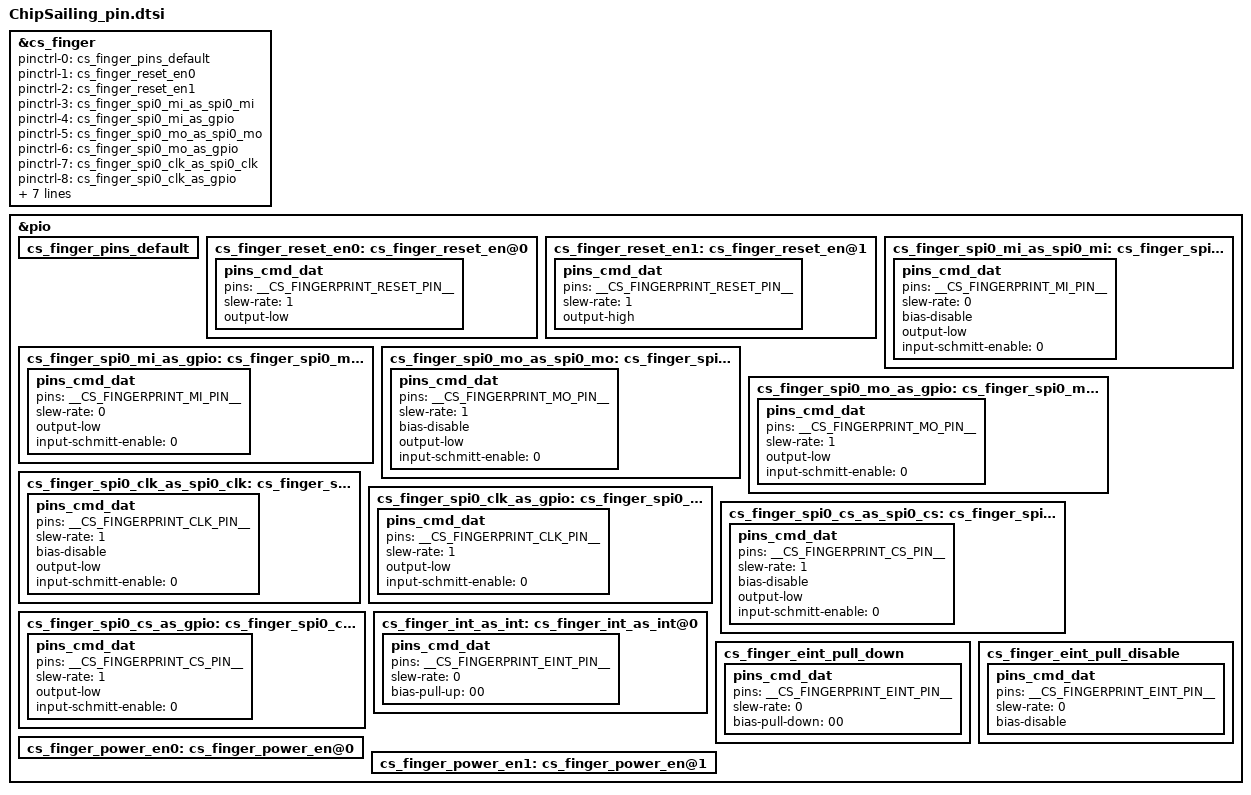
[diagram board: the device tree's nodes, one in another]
/*******************finger pin start ****************/


/*FINGERPRINT GPIO standardization*/
#define __CS_FINGERPRINT_EINT_EN_PIN_NUM__           5
#define __CS_FINGERPRINT_RESET_EN_PIN_NUM__          53
#define __CS_FINGERPRINT_EINT_PIN__                  PINMUX_GPIO5__FUNC_GPIO5
#define __CS_FINGERPRINT_RESET_PIN__                 PINMUX_GPIO53__FUNC_GPIO53 
#define __CS_FINGERPRINT_MI_PIN__          			 PINMUX_GPIO85__FUNC_SPI0_MI
#define __CS_FINGERPRINT_MO_PIN__     				 PINMUX_GPIO87__FUNC_SPI0_MO
#define __CS_FINGERPRINT_CLK_PIN__    				 PINMUX_GPIO88__FUNC_SPI0_CLK
#define __CS_FINGERPRINT_CS_PIN__    				 PINMUX_GPIO86__FUNC_SPI0_CSB

 
 
&cs_finger{
	pinctrl-names = "cs_finger_pins_default", "cs_finger_reset_en0","cs_finger_reset_en1","cs_finger_spi0_mi_as_spi0_mi","cs_finger_spi0_mi_as_gpio",
                          "cs_finger_spi0_mo_as_spi0_mo","cs_finger_spi0_mo_as_gpio","cs_finger_spi0_clk_as_spi0_clk","cs_finger_spi0_clk_as_gpio","cs_finger_spi0_cs_as_spi0_cs",
                          "cs_finger_spi0_cs_as_gpio","cs_finger_int_as_int","cs_finger_eint_pull_down","cs_finger_eint_pull_disable","cs_finger_power_off","cs_finger_power_on";
	pinctrl-0 = <&cs_finger_pins_default>;
	pinctrl-1 = <&cs_finger_reset_en0>;
	pinctrl-2 = <&cs_finger_reset_en1>;
	pinctrl-3 = <&cs_finger_spi0_mi_as_spi0_mi>;
	pinctrl-4 = <&cs_finger_spi0_mi_as_gpio>;
	pinctrl-5 = <&cs_finger_spi0_mo_as_spi0_mo>;
	pinctrl-6 = <&cs_finger_spi0_mo_as_gpio>;
	pinctrl-7 = <&cs_finger_spi0_clk_as_spi0_clk>;
	pinctrl-8= <&cs_finger_spi0_clk_as_gpio>;
	pinctrl-9= <&cs_finger_spi0_cs_as_spi0_cs>;
	pinctrl-10= <&cs_finger_spi0_cs_as_gpio>;
	pinctrl-11= <&cs_finger_int_as_int>;
	pinctrl-12= <&cs_finger_eint_pull_down>;
	pinctrl-13= <&cs_finger_eint_pull_disable>;
	pinctrl-14 = <&cs_finger_power_en0>;
	pinctrl-15 = <&cs_finger_power_en1>;
	status = "okay";
}; 



/*   GPIO standardization */
&pio {
	cs_finger_pins_default:cs_finger_pins_default{
	};
 
	cs_finger_reset_en0:cs_finger_reset_en@0{
		    pins_cmd_dat {
			pins = <__CS_FINGERPRINT_RESET_PIN__>;
			slew-rate = <1>;
			output-low; 
		};
	};
	cs_finger_reset_en1:cs_finger_reset_en@1{
		    pins_cmd_dat {
			pins = <__CS_FINGERPRINT_RESET_PIN__>;
			slew-rate = <1>;
			output-high;
		};
	};
	cs_finger_spi0_mi_as_spi0_mi:cs_finger_spi0_mi_as_spi0_mi@0{
		    pins_cmd_dat {
			pins = <__CS_FINGERPRINT_MI_PIN__>;
			slew-rate = <0>;
			bias-disable;
			output-low;
			input-schmitt-enable = <0>;
		};
	};
 	
	cs_finger_spi0_mi_as_gpio:cs_finger_spi0_mi_as_gpio@0{
		    pins_cmd_dat {
			pins = <__CS_FINGERPRINT_MI_PIN__>;
			slew-rate = <0>;
			output-low;
			input-schmitt-enable = <0>;
		};
	};
	
 
	cs_finger_spi0_mo_as_spi0_mo:cs_finger_spi0_mo_as_spi0_mo@0{
		    pins_cmd_dat {
			pins = <__CS_FINGERPRINT_MO_PIN__>;
			slew-rate = <1>;
			bias-disable;
			output-low;
			input-schmitt-enable = <0>;
		};
	};
 
	cs_finger_spi0_mo_as_gpio:cs_finger_spi0_mo_as_gpio@0{
		    pins_cmd_dat {
			pins = <__CS_FINGERPRINT_MO_PIN__>;
			slew-rate = <1>;
			output-low;
			input-schmitt-enable = <0>;
		};
	};
	cs_finger_spi0_clk_as_spi0_clk:cs_finger_spi0_clk_as_spi0_clk@0{
		    pins_cmd_dat {
			pins = <__CS_FINGERPRINT_CLK_PIN__>;
			slew-rate = <1>;
			bias-disable;
			output-low;
			input-schmitt-enable = <0>;
		};
	};
	cs_finger_spi0_clk_as_gpio:cs_finger_spi0_clk_as_gpio@0{
		    pins_cmd_dat {
			pins = <__CS_FINGERPRINT_CLK_PIN__>;
			slew-rate = <1>;
			output-low;
			input-schmitt-enable = <0>;
		};
	};
	cs_finger_spi0_cs_as_spi0_cs:cs_finger_spi0_cs_as_spi0_cs@0{
		    pins_cmd_dat {
			pins = <__CS_FINGERPRINT_CS_PIN__>;
			slew-rate = <1>;
			bias-disable;
			output-low;
			input-schmitt-enable = <0>;
		};
	};
	cs_finger_spi0_cs_as_gpio:cs_finger_spi0_cs_as_gpio@0{
		    pins_cmd_dat {
			pins = <__CS_FINGERPRINT_CS_PIN__>;
			slew-rate = <1>;
			output-low;
			input-schmitt-enable = <0>;
		};
	};
	cs_finger_int_as_int: cs_finger_int_as_int@0{
			pins_cmd_dat {
				pins = <__CS_FINGERPRINT_EINT_PIN__>;
				slew-rate = <0>;
				bias-pull-up = <00>;
			};
	};
	
	cs_finger_eint_pull_down: cs_finger_eint_pull_down { 
   pins_cmd_dat { 
     pins = <__CS_FINGERPRINT_EINT_PIN__>; 
     slew-rate = <0>; 
     bias-pull-down = <00>; 
   }; 
 }; 
  cs_finger_eint_pull_disable: cs_finger_eint_pull_disable { 
   pins_cmd_dat { 
     pins = <__CS_FINGERPRINT_EINT_PIN__>; 
     slew-rate = <0>; 
     bias-disable; 
   }; 
 };
	cs_finger_power_en0:cs_finger_power_en@0{
				// pins_cmd_dat {
					 //pins = <PINMUX_GPIO13__FUNC_GPIO13>;
					 //slew-rate = <1>;
					 //output-low;
				 //};
			 };
	cs_finger_power_en1:cs_finger_power_en@1{
				 //pins_cmd_dat {
					 //pins = <PINMUX_GPIO13__FUNC_GPIO13>;
					 //slew-rate = <1>;
					 //output-high;
				 //};
			 }; 
};
/*******************finger pin end****************/
 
